# uart: IP-XACT component
VLNV opencollate.example:synthetic:uart:1.0

## Bus interfaces (logical=physical port)
CLOCK: slave opencollate.example:signal:clock:1.0
  CLK=clk_i

## Ports
in clk_i
in rst_ni
in tx_en_i
in data_i[7:0]
out data_o[7:0]
out irq_o
out tx_active_o
inout VDD_CORE
inout VSS

## Address spaces and blocks
registers.uart_regs: base 0x40001000, range 0x100, width 32, register

## Registers
Registers are 32-bit, read-write, reset 0x0 unless marked. A register's access mark holds for its fields unless they carry their own. Offsets are from the block's base; lines under a group give offsets from that group; [hi:lo] are bit positions; {n}, {i} and the like mark numbered series; 'fields as' and 'values as' point back to an identical list; <NAME> marks a mode.

## registers.uart_regs
Base 0x40001000
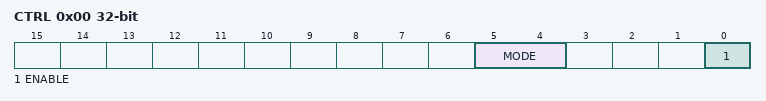
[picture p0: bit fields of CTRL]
0x00 CTRL (reset mask 0x1)
  [5:4] MODE, [0] ENABLE
